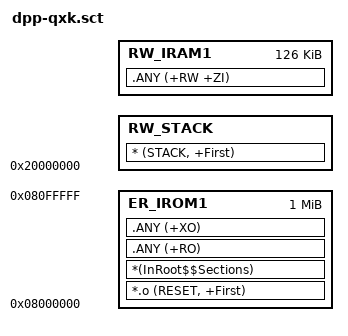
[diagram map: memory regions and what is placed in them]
; *************************************************************
; *** Scatter-Loading Description File generated by uVision ***
;
; Adapted by Quantum Leaps:
; moved STACK as the first section in RW_IRAM1
; *************************************************************

LR_IROM1 0x08000000 0x00100000  {    ; load region size_region
  ER_IROM1 0x08000000 0x00100000  {  ; load address = execution address
   *.o (RESET, +First)
   *(InRoot$$Sections)
   .ANY (+RO)
   .ANY (+XO)
  }
  RW_STACK 0x20000000 {              ; <== Quantum Leaps 
   * (STACK, +First)
  }
  RW_IRAM1 +0 (0x00020000 - 2048) {  ; NOTE: 2048 assumed for STACK size!
   .ANY (+RW +ZI)
  }
}

